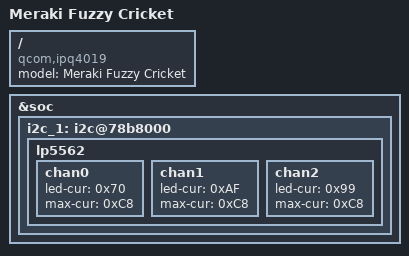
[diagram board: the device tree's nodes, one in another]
/* Copyright (c) 2015, The Linux Foundation. All rights reserved.
 *
 * Permission to use, copy, modify, and/or distribute this software for any
 * purpose with or without fee is hereby granted, provided that the above
 * copyright notice and this permission notice appear in all copies.
 *
 * THE SOFTWARE IS PROVIDED "AS IS" AND THE AUTHOR DISCLAIMS ALL WARRANTIES
 * WITH REGARD TO THIS SOFTWARE INCLUDING ALL IMPLIED WARRANTIES OF
 * MERCHANTABILITY AND FITNESS. IN NO EVENT SHALL THE AUTHOR BE LIABLE FOR
 * ANY SPECIAL, DIRECT, INDIRECT, OR CONSEQUENTIAL DAMAGES OR ANY DAMAGES
 * WHATSOEVER RESULTING FROM LOSS OF USE, DATA OR PROFITS, WHETHER IN AN
 * ACTION OF CONTRACT, NEGLIGENCE OR OTHER TORTIOUS ACTION, ARISING OUT OF
 * OR IN CONNECTION WITH THE USE OR PERFORMANCE OF THIS SOFTWARE.
 *
 */

#include "wired-arm-qca.dtsi"

/ {
	model = "Meraki Fuzzy Cricket";
	compatible = "qcom,ipq4019","meraki,fuzzy cricket";
};

&soc {
	i2c_1: i2c@78b8000 {
	       lp5562 {
		       chan0 {
			       led-cur = /bits/ 8 <0x70>;
			       max-cur = /bits/ 8 <0xC8>;
		       };
		       chan1 {
			       led-cur = /bits/ 8 <0xAF>;
			       max-cur = /bits/ 8 <0xC8>;
		       };
		       chan2 {
			       led-cur = /bits/ 8 <0x99>;
			       max-cur = /bits/ 8 <0xC8>;
		       };
	       };
       };
};

